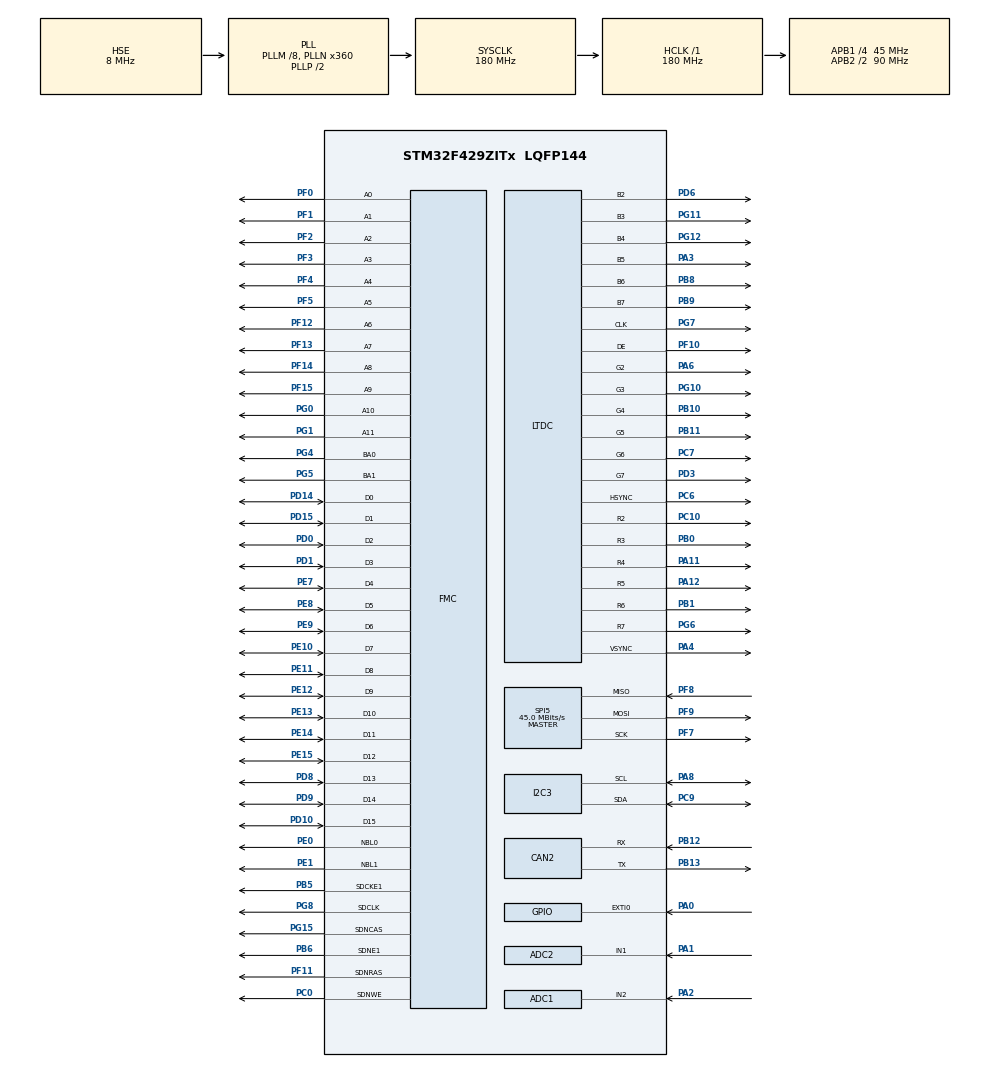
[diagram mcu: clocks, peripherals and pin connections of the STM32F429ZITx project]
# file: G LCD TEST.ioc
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ADC1.Channel-1\#ChannelRegularConversion=ADC_CHANNEL_TEMPSENSOR
ADC1.ContinuousConvMode=ENABLE
ADC1.EOCSelection=ADC_EOC_SEQ_CONV
ADC1.NbrOfConversion=1
ADC1.NbrOfConversionFlag=1
ADC1.Rank-1\#ChannelRegularConversion=1
ADC1.SamplingTime-1\#ChannelRegularConversion=ADC_SAMPLETIME_3CYCLES
ADC1.ScanConvMode=DISABLE
ADC1.master=1
ADC2.Channel-0\#ChannelRegularConversion=ADC_CHANNEL_1
ADC2.ContinuousConvMode=ENABLE
ADC2.NbrOfConversionFlag=1
ADC2.Rank-0\#ChannelRegularConversion=1
ADC2.SamplingTime-0\#ChannelRegularConversion=ADC_SAMPLETIME_3CYCLES
ADC2.ScanConvMode=DISABLE
CAN2.BS1=CAN_BS1_3TQ
CAN2.BS2=CAN_BS2_5TQ
CAN2.CalculateTimeQuantum=355.55555555555554
DMA2D.ColorMode=DMA2D_OUTPUT_RGB565
DMA2D.LineOffsetMode=DMA2D_LOM_PIXELS
LTDC.ActiveH=320
LTDC.ActiveW=240
LTDC.HBP=2
LTDC.HFP=2
LTDC.HSync=4
LTDC.VBP=7
LTDC.VFP=6
LTDC.VSPolarity=LTDC_VSPOLARITY_AL
LTDC.VSync=8
Mcu.Family=STM32F4
Mcu.Name=STM32F429ZITx
Mcu.Package=LQFP144
NVIC.ADC_IRQn=true\:0\:0\:false\:false\:true\:true\:true
NVIC.CAN2_RX0_IRQn=true\:0\:0\:false\:false\:true\:true\:true
NVIC.EXTI0_IRQn=true\:0\:0\:true\:false\:true\:true\:true
NVIC.I2C3_ER_IRQn=true\:0\:0\:false\:false\:true\:true\:true
NVIC.PriorityGroup=NVIC_PRIORITYGROUP_4
PA0/WKUP.Signal=GPXTI0
PA1.Signal=ADCx_IN1
PA11.Mode=RGB666
PA11.Signal=LTDC_R4
PA12.Mode=RGB666
PA12.Signal=LTDC_R5
PA2.Signal=ADCx_IN2
PA3.Mode=RGB666
PA3.Signal=LTDC_B5
PA4.Mode=RGB666
PA4.Signal=LTDC_VSYNC
PA6.Mode=RGB666
PA6.Signal=LTDC_G2
PA8.Mode=I2C
PA8.Signal=I2C3_SCL
PB0.Mode=RGB666
PB0.Signal=LTDC_R3
PB1.Mode=RGB666
PB1.Signal=LTDC_R6
PB10.Mode=RGB666
PB10.Signal=LTDC_G4
PB11.Mode=RGB666
PB11.Signal=LTDC_G5
PB12.Mode=Slave
PB12.Signal=CAN2_RX
PB13.Mode=Slave
PB13.Signal=CAN2_TX
PB5.Mode=SdramChipSelect2_1
PB5.Signal=FMC_SDCKE1
PB6.Mode=SdramChipSelect2_1
PB6.Signal=FMC_SDNE1
PB8.Mode=RGB666
PB8.Signal=LTDC_B6
PB9.Mode=RGB666
PB9.Signal=LTDC_B7
PC0.Signal=FMC_SDNWE
PC10.Mode=RGB666
PC10.Signal=LTDC_R2
PC6.Mode=RGB666
PC6.Signal=LTDC_HSYNC
PC7.Mode=RGB666
PC7.Signal=LTDC_G6
PC9.Mode=I2C
PC9.Signal=I2C3_SDA
PD0.Signal=FMC_D2_DA2
PD1.Signal=FMC_D3_DA3
PD10.Signal=FMC_D15_DA15
PD14.Signal=FMC_D0_DA0
PD15.Signal=FMC_D1_DA1
PD3.Mode=RGB666
PD3.Signal=LTDC_G7
PD6.Mode=RGB666
PD6.Signal=LTDC_B2
PD8.Signal=FMC_D13_DA13
PD9.Signal=FMC_D14_DA14
PE0.Signal=FMC_NBL0
PE1.Signal=FMC_NBL1
PE10.Signal=FMC_D7_DA7
PE11.Signal=FMC_D8_DA8
PE12.Signal=FMC_D9_DA9
PE13.Signal=FMC_D10_DA10
PE14.Signal=FMC_D11_DA11
PE15.Signal=FMC_D12_DA12
PE7.Signal=FMC_D4_DA4
PE8.Signal=FMC_D5_DA5
PE9.Signal=FMC_D6_DA6
PF0.Signal=FMC_A0
PF1.Signal=FMC_A1
PF10.Mode=RGB666
PF10.Signal=LTDC_DE
PF11.Signal=FMC_SDNRAS
PF12.Signal=FMC_A6
PF13.Signal=FMC_A7
PF14.Signal=FMC_A8
PF15.Signal=FMC_A9
PF2.Signal=FMC_A2
PF3.Signal=FMC_A3
PF4.Signal=FMC_A4
PF5.Signal=FMC_A5
PF7.Mode=Full_Duplex_Master
PF7.Signal=SPI5_SCK
PF8.Mode=Full_Duplex_Master
PF8.Signal=SPI5_MISO
PF9.Mode=Full_Duplex_Master
PF9.Signal=SPI5_MOSI
PG0.Signal=FMC_A10
PG1.Signal=FMC_A11
PG10.Mode=RGB666
PG10.Signal=LTDC_G3
PG11.Mode=RGB666
PG11.Signal=LTDC_B3
PG12.Mode=RGB666
PG12.Signal=LTDC_B4
PG15.Signal=FMC_SDNCAS
PG4.Signal=FMC_A14_BA0
PG5.Signal=FMC_A15_BA1
PG6.Mode=RGB666
PG6.Signal=LTDC_R7
PG7.Mode=RGB666
PG7.Signal=LTDC_CLK
PG8.Signal=FMC_SDCLK
PH0/OSC_IN.Mode=HSE-External-Oscillator
PH0/OSC_IN.Signal=RCC_OSC_IN
PH1/OSC_OUT.Mode=HSE-External-Oscillator
PH1/OSC_OUT.Signal=RCC_OSC_OUT
ProjectManager.HeapSize=0x200
ProjectManager.StackSize=0x400
ProjectManager.TargetToolchain=MDK-ARM V5
RCC.48MHZClocksFreq_Value=90000000
RCC.AHBFreq_Value=180000000
RCC.APB1CLKDivider=RCC_HCLK_DIV4
RCC.APB1Freq_Value=45000000
RCC.APB1TimFreq_Value=90000000
RCC.APB2CLKDivider=RCC_HCLK_DIV2
RCC.APB2Freq_Value=90000000
RCC.APB2TimFreq_Value=180000000
RCC.CortexFreq_Value=180000000
RCC.HCLKFreq_Value=180000000
RCC.HSE_VALUE=8000000
RCC.HSI_VALUE=16000000
RCC.LSE_VALUE=32768
RCC.PLLM=8
RCC.PLLN=360
RCC.PLLSAIN=432
RCC.PLLSourceVirtual=RCC_PLLSOURCE_HSE
RCC.SYSCLKFreq_VALUE=180000000
RCC.SYSCLKSource=RCC_SYSCLKSOURCE_PLLCLK
RCC.VCOOutputFreq_Value=360000000
SH.ADCx_IN1.0=ADC2_IN1,IN1
SH.ADCx_IN2.0=ADC1_IN2,IN2
SH.FMC_A0.0=FMC_A0,12b-sda1
SH.FMC_A1.0=FMC_A1,12b-sda1
SH.FMC_A10.0=FMC_A10,12b-sda1
SH.FMC_A11.0=FMC_A11,12b-sda1
SH.FMC_A14_BA0.0=FMC_BA0,FourSdramBanks1
SH.FMC_A15_BA1.0=FMC_BA1,FourSdramBanks1
SH.FMC_A2.0=FMC_A2,12b-sda1
SH.FMC_A3.0=FMC_A3,12b-sda1
SH.FMC_A4.0=FMC_A4,12b-sda1
SH.FMC_A5.0=FMC_A5,12b-sda1
SH.FMC_A6.0=FMC_A6,12b-sda1
SH.FMC_A7.0=FMC_A7,12b-sda1
SH.FMC_A8.0=FMC_A8,12b-sda1
SH.FMC_A9.0=FMC_A9,12b-sda1
SH.FMC_D0_DA0.0=FMC_D0,sd-16b-d1
SH.FMC_D10_DA10.0=FMC_D10,sd-16b-d1
SH.FMC_D11_DA11.0=FMC_D11,sd-16b-d1
SH.FMC_D12_DA12.0=FMC_D12,sd-16b-d1
SH.FMC_D13_DA13.0=FMC_D13,sd-16b-d1
SH.FMC_D14_DA14.0=FMC_D14,sd-16b-d1
SH.FMC_D15_DA15.0=FMC_D15,sd-16b-d1
SH.FMC_D1_DA1.0=FMC_D1,sd-16b-d1
SH.FMC_D2_DA2.0=FMC_D2,sd-16b-d1
SH.FMC_D3_DA3.0=FMC_D3,sd-16b-d1
SH.FMC_D4_DA4.0=FMC_D4,sd-16b-d1
SH.FMC_D5_DA5.0=FMC_D5,sd-16b-d1
SH.FMC_D6_DA6.0=FMC_D6,sd-16b-d1
SH.FMC_D7_DA7.0=FMC_D7,sd-16b-d1
SH.FMC_D8_DA8.0=FMC_D8,sd-16b-d1
SH.FMC_D9_DA9.0=FMC_D9,sd-16b-d1
SH.FMC_NBL0.0=FMC_NBL0,Sd2ByteEnable1
SH.FMC_NBL1.0=FMC_NBL1,Sd2ByteEnable1
SH.FMC_SDCLK.0=FMC_SDCLK,12b-sda1
SH.FMC_SDNCAS.0=FMC_SDNCAS,12b-sda1
SH.FMC_SDNRAS.0=FMC_SDNRAS,12b-sda1
SH.FMC_SDNWE.0=FMC_SDNWE,12b-sda1
SPI5.BaudRatePrescaler=SPI_BAUDRATEPRESCALER_2
SPI5.CalculateBaudRate=45.0 MBits/s
SPI5.Direction=SPI_DIRECTION_2LINES
SPI5.Mode=SPI_MODE_MASTER
SPI5.VirtualType=VM_MASTER
VP_ADC1_TempSens_Input.Mode=IN-TempSens
VP_DMA2D_VS_DMA2D.Mode=DMA2D_Activate
board=custom

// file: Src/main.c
/* USER CODE BEGIN Header */
/**
  ******************************************************************************
  * @file           : main.c
  * @brief          : Main program body
  ******************************************************************************
  * @attention
  *
  * <h2><center>&copy; Copyright (c) 2020 STMicroelectronics.
  * All rights reserved.</center></h2>
  *
  * This software component is licensed by ST under BSD 3-Clause license,
  * the "License"; You may not use this file except in compliance with the
  * License. You may obtain a copy of the License at:
  *                        opensource.org/licenses/BSD-3-Clause
  *
  ******************************************************************************
  */
/* USER CODE END Header */

#include "main.h"

/* USER CODE BEGIN Includes */
#include "stm32f429I_discovery_lcd.h"
#include "stm32f4xx.h"                  // Device header
/* USER CODE END Includes */

ADC_HandleTypeDef hadc1;
ADC_HandleTypeDef hadc2;

CAN_HandleTypeDef hcan2;

DMA2D_HandleTypeDef hdma2d;

I2C_HandleTypeDef hi2c3;

LTDC_HandleTypeDef hltdc;

SPI_HandleTypeDef hspi5;

SDRAM_HandleTypeDef hsdram1;

/* USER CODE BEGIN PV */

CAN_TxMailBox_TypeDef        TxM;
CAN_RxMailBox_TypeDef 			 RxM;

CAN_FilterTypeDef sFilterConfig;
uint8_t a;

	uint16_t x=0;
	uint32_t data=0;
	char yazi[16]="  ";
	uint32_t data1=0;
	char yazi1[16]="  ";

/* USER CODE END PV */

void SystemClock_Config(void);
static void MX_GPIO_Init(void);
static void MX_DMA2D_Init(void);
static void MX_FMC_Init(void);
static void MX_I2C3_Init(void);
static void MX_LTDC_Init(void);
static void MX_SPI5_Init(void);
static void MX_ADC1_Init(void);
static void MX_ADC2_Init(void);
static void MX_CAN2_Init(void);

int main(void)
{

  /* MCU Configuration--------------------------------------------------------*/

  /* Reset of all peripherals, Initializes the Flash interface and the Systick. */
  HAL_Init();

  /* Configure the system clock */
  SystemClock_Config();

  /* Initialize all configured peripherals */
  MX_GPIO_Init();
  MX_DMA2D_Init();
  MX_FMC_Init();
  MX_I2C3_Init();
  MX_LTDC_Init();
  MX_SPI5_Init();
  MX_ADC1_Init();
  MX_ADC2_Init();
  MX_CAN2_Init();
  /* USER CODE BEGIN 2 */

	hcan2.sTxMailBox=&TxM;
hcan2.pRxMsg=&RxM;

sFilterConfig.FilterMode=CAN_FILTERMODE_IDLIST;
sFilterConfig.FilterScale=CAN_FILTERSCALE_32BIT;
sFilterConfig.FilterIdHigh=0x245<<5;
sFilterConfig.FilterIdLow=0;
sFilterConfig.FilterMaskIdHigh=0;
sFilterConfig.FilterMaskIdLow=0;
sFilterConfig.FilterFIFOAssignment=0;
sFilterConfig.FilterBank=14;
HAL_CAN_ConfigFilter(&hcan2, &sFilterConfig);

hcan2.pTxMsg->StdId=0x245;
hcan2.pTxMsg->RTR=CAN_RTR_DATA;
hcan2.pTxMsg->IDE=CAN_ID_STD;
hcan2.pTxMsg->DLC=8;
CAN1 ->FA1R=0x00000001;

HAL_CAN_Receive_IT(&hcan2, CAN_RX_FIFO0);

	HAL_ADC_Start(&hadc1);
	HAL_ADC_Start(&hadc2);
	BSP_LCD_Init();

	BSP_LCD_LayerDefaultInit(LCD_BACKGROUND_LAYER,LCD_FRAME_BUFFER);
	BSP_LCD_LayerDefaultInit(LCD_FOREGROUND_LAYER,LCD_FRAME_BUFFER);
	BSP_LCD_SelectLayer(LCD_FOREGROUND_LAYER);
	BSP_LCD_DisplayOn();

	BSP_LCD_Clear(LCD_COLOR_BLUE);
	BSP_LCD_SetBackColor(LCD_COLOR_BLUE);
	BSP_LCD_SetFont(&Font20);
	data= HAL_ADC_GetValue(&hadc1);
	sprintf(yazi,"%4d",data);
	data= HAL_ADC_GetValue(&hadc2);
	sprintf(yazi1,"%4d",data1);

  /* USER CODE END 2 */

  /* Infinite loop */
  while (1)
  {

    /* USER CODE BEGIN 3 */
		HAL_ADC_PollForConversion(&hadc2, 100);
	HAL_ADC_PollForConversion(&hadc1, 100);
		data= HAL_ADC_GetValue(&hadc2);
		data= HAL_ADC_GetValue(&hadc1);
		sprintf(yazi,"%u   ",data);
		sprintf(yazi1,"%u   ",data1);

		BSP_LCD_SetTextColor(LCD_COLOR_CYAN);

			BSP_LCD_SetBackColor(LCD_COLOR_BLUE);
	/*
		BSP_LCD_DisplayStringAtLine(1,(uint8_t*) "   SENSOR   ");
			BSP_LCD_SetFont(&Font20);
		BSP_LCD_DisplayStringAtLine(3,(uint8_t*) "   SENSOR");
		BSP_LCD_SetFont(&Font12);
		BSP_LCD_DisplayStringAtLine(5,(uint8_t*)"  SENSOR");
		BSP_LCD_DisplayStringAtLine(9,(uint8_t*) "   SENSOR   ");
		*/

		BSP_LCD_DisplayStringAt(70, 40, yazi, 1);
		BSP_LCD_DisplayStringAt(180, 40, yazi, 1);
		BSP_LCD_DisplayStringAt(70, 120, yazi, 1);
		BSP_LCD_DisplayStringAt(180, 120, yazi,1);
		BSP_LCD_DisplayStringAt(70, 180, yazi, 1);
		BSP_LCD_DisplayStringAt(180, 180, yazi,1);
	BSP_LCD_GetXSize();

		/*		BSP_LCD_SetBackColor(LCD_COLOR_WHITE);
BSP_LCD_DisplayStringAt(20, 30, yazi1, 90);
BSP_LCD_DisplayStringAt(80, 150, yazi1, 270);
BSP_LCD_DisplayStringAt(200, 200, yazi1, 360);
*/

	BSP_LCD_SetTextColor(LCD_COLOR_YELLOW);

		BSP_LCD_DrawRect(30, 85, 130, 20);
		BSP_LCD_DrawRect(30, 205, 130, 20);
		BSP_LCD_DrawRect(30, 145, 130, 20);
		BSP_LCD_DrawRect(65, 100, 70, 100);
		BSP_LCD_DrawRect(65, 120, 70, 100);

		BSP_LCD_FillCircle(40, 95, 15);
		BSP_LCD_FillCircle(155, 95, 15);
		BSP_LCD_FillCircle(40, 155, 15);
		BSP_LCD_FillCircle(155, 155, 15);
		BSP_LCD_FillCircle(40, 215, 15);
		BSP_LCD_FillCircle(155, 215, 15);

		if(x==1)
		{

		BSP_LCD_SetTextColor(LCD_COLOR_RED);
			BSP_LCD_FillCircle(220, 290, 18);
			BSP_LCD_FillCircle(220, 20, 18);
			HAL_Delay(1000);

	}
	if(x==0)
		{
			BSP_LCD_SetTextColor(LCD_COLOR_BLUE);
		BSP_LCD_FillCircle(220, 290, 18);
			BSP_LCD_FillCircle(220, 20, 18);

		HAL_Delay(1000);

	}
		if(data<900)
		{
			BSP_LCD_SetTextColor(LCD_COLOR_RED);
		BSP_LCD_FillCircle(40, 95, 15);
		BSP_LCD_FillCircle(155, 95, 15);
		BSP_LCD_FillCircle(40, 155, 15);
		BSP_LCD_FillCircle(155, 155, 15);
		BSP_LCD_FillCircle(40, 215, 15);
		BSP_LCD_FillCircle(155, 215, 15);

		HAL_Delay(1000);

	}
  }
  /* USER CODE END 3 */
}

void SystemClock_Config(void)
{
  RCC_OscInitTypeDef RCC_OscInitStruct = {0};
  RCC_ClkInitTypeDef RCC_ClkInitStruct = {0};
  RCC_PeriphCLKInitTypeDef PeriphClkInitStruct = {0};

  /** Configure the main internal regulator output voltage
  */
  __HAL_RCC_PWR_CLK_ENABLE();
  __HAL_PWR_VOLTAGESCALING_CONFIG(PWR_REGULATOR_VOLTAGE_SCALE1);
  /** Initializes the CPU, AHB and APB busses clocks
  */
  RCC_OscInitStruct.OscillatorType = RCC_OSCILLATORTYPE_HSE;
  RCC_OscInitStruct.HSEState = RCC_HSE_ON;
  RCC_OscInitStruct.PLL.PLLState = RCC_PLL_ON;
  RCC_OscInitStruct.PLL.PLLSource = RCC_PLLSOURCE_HSE;
  RCC_OscInitStruct.PLL.PLLM = 8;
  RCC_OscInitStruct.PLL.PLLN = 360;
  RCC_OscInitStruct.PLL.PLLP = RCC_PLLP_DIV2;
  RCC_OscInitStruct.PLL.PLLQ = 4;
  if (HAL_RCC_OscConfig(&RCC_OscInitStruct) != HAL_OK)
  {
    Error_Handler();
  }
  /** Activate the Over-Drive mode
  */
  if (HAL_PWREx_EnableOverDrive() != HAL_OK)
  {
    Error_Handler();
  }
  /** Initializes the CPU, AHB and APB busses clocks
  */
  RCC_ClkInitStruct.ClockType = RCC_CLOCKTYPE_HCLK|RCC_CLOCKTYPE_SYSCLK
                              |RCC_CLOCKTYPE_PCLK1|RCC_CLOCKTYPE_PCLK2;
  RCC_ClkInitStruct.SYSCLKSource = RCC_SYSCLKSOURCE_PLLCLK;
  RCC_ClkInitStruct.AHBCLKDivider = RCC_SYSCLK_DIV1;
  RCC_ClkInitStruct.APB1CLKDivider = RCC_HCLK_DIV4;
  RCC_ClkInitStruct.APB2CLKDivider = RCC_HCLK_DIV2;

  if (HAL_RCC_ClockConfig(&RCC_ClkInitStruct, FLASH_LATENCY_5) != HAL_OK)
  {
    Error_Handler();
  }
  PeriphClkInitStruct.PeriphClockSelection = RCC_PERIPHCLK_LTDC;
  PeriphClkInitStruct.PLLSAI.PLLSAIN = 432;
  PeriphClkInitStruct.PLLSAI.PLLSAIR = 2;
  PeriphClkInitStruct.PLLSAIDivR = RCC_PLLSAIDIVR_2;
  if (HAL_RCCEx_PeriphCLKConfig(&PeriphClkInitStruct) != HAL_OK)
  {
    Error_Handler();
  }
}

static void MX_ADC1_Init(void)
{

  ADC_ChannelConfTypeDef sConfig = {0};

  /** Configure the global features of the ADC (Clock, Resolution, Data Alignment and number of conversion)
  */
  hadc1.Instance = ADC1;
  hadc1.Init.ClockPrescaler = ADC_CLOCK_SYNC_PCLK_DIV4;
  hadc1.Init.Resolution = ADC_RESOLUTION_12B;
  hadc1.Init.ScanConvMode = DISABLE;
  hadc1.Init.ContinuousConvMode = ENABLE;
  hadc1.Init.DiscontinuousConvMode = DISABLE;
  hadc1.Init.ExternalTrigConvEdge = ADC_EXTERNALTRIGCONVEDGE_NONE;
  hadc1.Init.ExternalTrigConv = ADC_SOFTWARE_START;
  hadc1.Init.DataAlign = ADC_DATAALIGN_RIGHT;
  hadc1.Init.NbrOfConversion = 1;
  hadc1.Init.DMAContinuousRequests = DISABLE;
  hadc1.Init.EOCSelection = ADC_EOC_SEQ_CONV;
  if (HAL_ADC_Init(&hadc1) != HAL_OK)
  {
    Error_Handler();
  }
  /** Configure for the selected ADC regular channel its corresponding rank in the sequencer and its sample time.
  */
  sConfig.Channel = ADC_CHANNEL_TEMPSENSOR;
  sConfig.Rank = 1;
  sConfig.SamplingTime = ADC_SAMPLETIME_3CYCLES;
  if (HAL_ADC_ConfigChannel(&hadc1, &sConfig) != HAL_OK)
  {
    Error_Handler();
  }

}

static void MX_ADC2_Init(void)
{

  ADC_ChannelConfTypeDef sConfig = {0};

  /** Configure the global features of the ADC (Clock, Resolution, Data Alignment and number of conversion)
  */
  hadc2.Instance = ADC2;
  hadc2.Init.ClockPrescaler = ADC_CLOCK_SYNC_PCLK_DIV4;
  hadc2.Init.Resolution = ADC_RESOLUTION_12B;
  hadc2.Init.ScanConvMode = DISABLE;
  hadc2.Init.ContinuousConvMode = ENABLE;
  hadc2.Init.DiscontinuousConvMode = DISABLE;
  hadc2.Init.ExternalTrigConvEdge = ADC_EXTERNALTRIGCONVEDGE_NONE;
  hadc2.Init.ExternalTrigConv = ADC_SOFTWARE_START;
  hadc2.Init.DataAlign = ADC_DATAALIGN_RIGHT;
  hadc2.Init.NbrOfConversion = 1;
  hadc2.Init.DMAContinuousRequests = DISABLE;
  hadc2.Init.EOCSelection = ADC_EOC_SINGLE_CONV;
  if (HAL_ADC_Init(&hadc2) != HAL_OK)
  {
    Error_Handler();
  }
  /** Configure for the selected ADC regular channel its corresponding rank in the sequencer and its sample time.
  */
  sConfig.Channel = ADC_CHANNEL_1;
  sConfig.Rank = 1;
  sConfig.SamplingTime = ADC_SAMPLETIME_3CYCLES;
  if (HAL_ADC_ConfigChannel(&hadc2, &sConfig) != HAL_OK)
  {
    Error_Handler();
  }

}

static void MX_CAN2_Init(void)
{

  hcan2.Instance = CAN2;
  hcan2.Init.Prescaler = 16;
  hcan2.Init.Mode = CAN_MODE_NORMAL;
  hcan2.Init.SyncJumpWidth = CAN_SJW_1TQ;
  hcan2.Init.TimeSeg1 = CAN_BS1_3TQ;
  hcan2.Init.TimeSeg2 = CAN_BS2_5TQ;
  hcan2.Init.TimeTriggeredMode = DISABLE;
  hcan2.Init.AutoBusOff = DISABLE;
  hcan2.Init.AutoWakeUp = DISABLE;
  hcan2.Init.AutoRetransmission = DISABLE;
  hcan2.Init.ReceiveFifoLocked = DISABLE;
  hcan2.Init.TransmitFifoPriority = DISABLE;
  if (HAL_CAN_Init(&hcan2) != HAL_OK)
  {
    Error_Handler();
  }

}

static void MX_DMA2D_Init(void)
{

  hdma2d.Instance = DMA2D;
  hdma2d.Init.Mode = DMA2D_M2M;
  hdma2d.Init.ColorMode = DMA2D_OUTPUT_RGB565;
  hdma2d.Init.OutputOffset = 0;
  hdma2d.LayerCfg[1].InputOffset = 0;
  hdma2d.LayerCfg[1].InputColorMode = DMA2D_INPUT_RGB565;
  hdma2d.LayerCfg[1].AlphaMode = DMA2D_NO_MODIF_ALPHA;
  hdma2d.LayerCfg[1].InputAlpha = 0;
  if (HAL_DMA2D_Init(&hdma2d) != HAL_OK)
  {
    Error_Handler();
  }
  if (HAL_DMA2D_ConfigLayer(&hdma2d, 1) != HAL_OK)
  {
    Error_Handler();
  }

}

static void MX_I2C3_Init(void)
{

  hi2c3.Instance = I2C3;
  hi2c3.Init.ClockSpeed = 100000;
  hi2c3.Init.DutyCycle = I2C_DUTYCYCLE_2;
  hi2c3.Init.OwnAddress1 = 0;
  hi2c3.Init.AddressingMode = I2C_ADDRESSINGMODE_7BIT;
  hi2c3.Init.DualAddressMode = I2C_DUALADDRESS_DISABLE;
  hi2c3.Init.OwnAddress2 = 0;
  hi2c3.Init.GeneralCallMode = I2C_GENERALCALL_DISABLE;
  hi2c3.Init.NoStretchMode = I2C_NOSTRETCH_DISABLE;
  if (HAL_I2C_Init(&hi2c3) != HAL_OK)
  {
    Error_Handler();
  }
  /** Configure Analogue filter
  */
  if (HAL_I2CEx_ConfigAnalogFilter(&hi2c3, I2C_ANALOGFILTER_ENABLE) != HAL_OK)
  {
    Error_Handler();
  }
  /** Configure Digital filter
  */
  if (HAL_I2CEx_ConfigDigitalFilter(&hi2c3, 0) != HAL_OK)
  {
    Error_Handler();
  }

}

static void MX_LTDC_Init(void)
{

  LTDC_LayerCfgTypeDef pLayerCfg = {0};
  LTDC_LayerCfgTypeDef pLayerCfg1 = {0};

  hltdc.Instance = LTDC;
  hltdc.Init.HSPolarity = LTDC_HSPOLARITY_AL;
  hltdc.Init.VSPolarity = LTDC_VSPOLARITY_AL;
  hltdc.Init.DEPolarity = LTDC_DEPOLARITY_AL;
  hltdc.Init.PCPolarity = LTDC_PCPOLARITY_IPC;
  hltdc.Init.HorizontalSync = 3;
  hltdc.Init.VerticalSync = 7;
  hltdc.Init.AccumulatedHBP = 5;
  hltdc.Init.AccumulatedVBP = 14;
  hltdc.Init.AccumulatedActiveW = 245;
  hltdc.Init.AccumulatedActiveH = 334;
  hltdc.Init.TotalWidth = 247;
  hltdc.Init.TotalHeigh = 340;
  hltdc.Init.Backcolor.Blue = 0;
  hltdc.Init.Backcolor.Green = 0;
  hltdc.Init.Backcolor.Red = 0;
  if (HAL_LTDC_Init(&hltdc) != HAL_OK)
  {
    Error_Handler();
  }
  pLayerCfg.WindowX0 = 0;
  pLayerCfg.WindowX1 = 0;
  pLayerCfg.WindowY0 = 0;
  pLayerCfg.WindowY1 = 0;
  pLayerCfg.PixelFormat = LTDC_PIXEL_FORMAT_ARGB8888;
  pLayerCfg.Alpha = 0;
  pLayerCfg.Alpha0 = 0;
  pLayerCfg.BlendingFactor1 = LTDC_BLENDING_FACTOR1_CA;
  pLayerCfg.BlendingFactor2 = LTDC_BLENDING_FACTOR2_CA;
  pLayerCfg.FBStartAdress = 0;
  pLayerCfg.ImageWidth = 0;
  pLayerCfg.ImageHeight = 0;
  pLayerCfg.Backcolor.Blue = 0;
  pLayerCfg.Backcolor.Green = 0;
  pLayerCfg.Backcolor.Red = 0;
  if (HAL_LTDC_ConfigLayer(&hltdc, &pLayerCfg, 0) != HAL_OK)
  {
    Error_Handler();
  }
  pLayerCfg1.WindowX0 = 0;
  pLayerCfg1.WindowX1 = 0;
  pLayerCfg1.WindowY0 = 0;
  pLayerCfg1.WindowY1 = 0;
  pLayerCfg1.PixelFormat = LTDC_PIXEL_FORMAT_ARGB8888;
  pLayerCfg1.Alpha = 0;
  pLayerCfg1.Alpha0 = 0;
  pLayerCfg1.BlendingFactor1 = LTDC_BLENDING_FACTOR1_CA;
  pLayerCfg1.BlendingFactor2 = LTDC_BLENDING_FACTOR2_CA;
  pLayerCfg1.FBStartAdress = 0;
  pLayerCfg1.ImageWidth = 0;
  pLayerCfg1.ImageHeight = 0;
  pLayerCfg1.Backcolor.Blue = 0;
  pLayerCfg1.Backcolor.Green = 0;
  pLayerCfg1.Backcolor.Red = 0;
  if (HAL_LTDC_ConfigLayer(&hltdc, &pLayerCfg1, 1) != HAL_OK)
  {
    Error_Handler();
  }

}

static void MX_SPI5_Init(void)
{

  /* SPI5 parameter configuration*/
  hspi5.Instance = SPI5;
  hspi5.Init.Mode = SPI_MODE_MASTER;
  hspi5.Init.Direction = SPI_DIRECTION_2LINES;
  hspi5.Init.DataSize = SPI_DATASIZE_8BIT;
  hspi5.Init.CLKPolarity = SPI_POLARITY_LOW;
  hspi5.Init.CLKPhase = SPI_PHASE_1EDGE;
  hspi5.Init.NSS = SPI_NSS_SOFT;
  hspi5.Init.BaudRatePrescaler = SPI_BAUDRATEPRESCALER_2;
  hspi5.Init.FirstBit = SPI_FIRSTBIT_MSB;
  hspi5.Init.TIMode = SPI_TIMODE_DISABLE;
  hspi5.Init.CRCCalculation = SPI_CRCCALCULATION_DISABLE;
  hspi5.Init.CRCPolynomial = 10;
  if (HAL_SPI_Init(&hspi5) != HAL_OK)
  {
    Error_Handler();
  }

}

/* FMC initialization function */
static void MX_FMC_Init(void)
{

  FMC_SDRAM_TimingTypeDef SdramTiming = {0};

  /** Perform the SDRAM1 memory initialization sequence
  */
  hsdram1.Instance = FMC_SDRAM_DEVICE;
  /* hsdram1.Init */
  hsdram1.Init.SDBank = FMC_SDRAM_BANK2;
  hsdram1.Init.ColumnBitsNumber = FMC_SDRAM_COLUMN_BITS_NUM_8;
  hsdram1.Init.RowBitsNumber = FMC_SDRAM_ROW_BITS_NUM_12;
  hsdram1.Init.MemoryDataWidth = FMC_SDRAM_MEM_BUS_WIDTH_16;
  hsdram1.Init.InternalBankNumber = FMC_SDRAM_INTERN_BANKS_NUM_4;
  hsdram1.Init.CASLatency = FMC_SDRAM_CAS_LATENCY_1;
  hsdram1.Init.WriteProtection = FMC_SDRAM_WRITE_PROTECTION_DISABLE;
  hsdram1.Init.SDClockPeriod = FMC_SDRAM_CLOCK_DISABLE;
  hsdram1.Init.ReadBurst = FMC_SDRAM_RBURST_DISABLE;
  hsdram1.Init.ReadPipeDelay = FMC_SDRAM_RPIPE_DELAY_0;
  /* SdramTiming */
  SdramTiming.LoadToActiveDelay = 16;
  SdramTiming.ExitSelfRefreshDelay = 16;
  SdramTiming.SelfRefreshTime = 16;
  SdramTiming.RowCycleDelay = 16;
  SdramTiming.WriteRecoveryTime = 16;
  SdramTiming.RPDelay = 16;
  SdramTiming.RCDDelay = 16;

  if (HAL_SDRAM_Init(&hsdram1, &SdramTiming) != HAL_OK)
  {
    Error_Handler( );
  }

}

static void MX_GPIO_Init(void)
{
  GPIO_InitTypeDef GPIO_InitStruct = {0};

  /* GPIO Ports Clock Enable */
  __HAL_RCC_GPIOF_CLK_ENABLE();
  __HAL_RCC_GPIOH_CLK_ENABLE();
  __HAL_RCC_GPIOC_CLK_ENABLE();
  __HAL_RCC_GPIOA_CLK_ENABLE();
  __HAL_RCC_GPIOB_CLK_ENABLE();
  __HAL_RCC_GPIOG_CLK_ENABLE();
  __HAL_RCC_GPIOE_CLK_ENABLE();
  __HAL_RCC_GPIOD_CLK_ENABLE();

  /*Configure GPIO pin : PA0 */
  GPIO_InitStruct.Pin = GPIO_PIN_0;
  GPIO_InitStruct.Mode = GPIO_MODE_IT_RISING;
  GPIO_InitStruct.Pull = GPIO_NOPULL;
  HAL_GPIO_Init(GPIOA, &GPIO_InitStruct);

  /* EXTI interrupt init*/
  HAL_NVIC_SetPriority(EXTI0_IRQn, 0, 0);
  HAL_NVIC_EnableIRQ(EXTI0_IRQn);

}

void Error_Handler(void)
{
}

/************************ (C) COPYRIGHT STMicroelectronics *****END OF FILE****/
